# ioADuCM302x register map
Registers are 16-bit, access not given, no defined reset value unless marked. A register's access mark holds for its fields unless they carry their own. Addresses are absolute; registers are grouped by the start of their names; [hi:lo] are bit positions; {n}, {i} and the like mark numbered series.

## PMG0
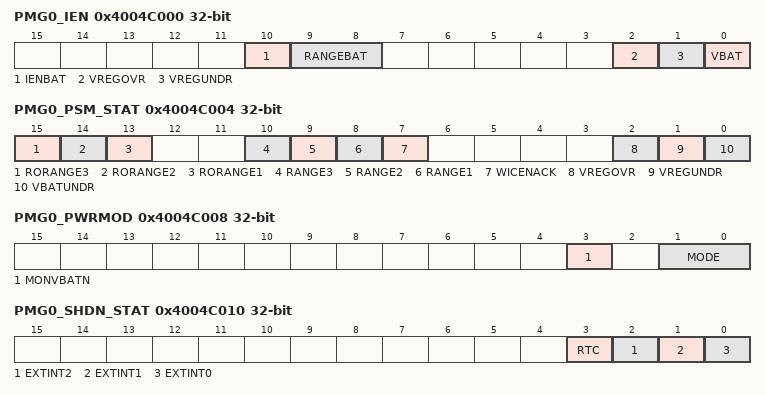
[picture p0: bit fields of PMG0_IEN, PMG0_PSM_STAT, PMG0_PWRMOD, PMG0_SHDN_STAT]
0x4004C000 PMG0_IEN 32-bit
  [10] IENBAT, [9:8] RANGEBAT, [2] VREGOVR, [1] VREGUNDR, [0] VBAT
0x4004C004 PMG0_PSM_STAT 32-bit
  [15] RORANGE3, [14] RORANGE2, [13] RORANGE1, [10] RANGE3, [9] RANGE2, [8] RANGE1, [7] WICENACK, [2] VREGOVR, [1] VREGUNDR, [0] VBATUNDR
0x4004C008 PMG0_PWRMOD 32-bit
  [3] MONVBATN, [1:0] MODE
0x4004C00C PMG0_PWRKEY 32-bit
  [15:0] VALUE
0x4004C010 PMG0_SHDN_STAT 32-bit
  [3] RTC, [2] EXTINT2, [1] EXTINT1, [0] EXTINT0
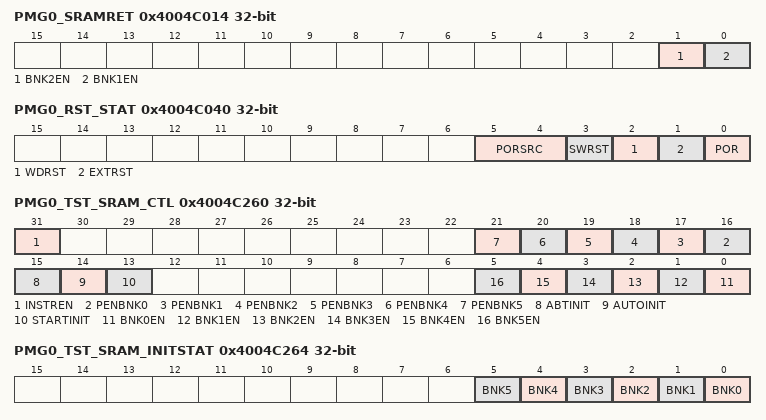
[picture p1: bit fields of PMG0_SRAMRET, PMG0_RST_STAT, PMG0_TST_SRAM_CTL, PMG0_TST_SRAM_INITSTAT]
0x4004C014 PMG0_SRAMRET 32-bit
  [1] BNK2EN, [0] BNK1EN
0x4004C040 PMG0_RST_STAT 32-bit
  [5:4] PORSRC, [3] SWRST, [2] WDRST, [1] EXTRST, [0] POR
0x4004C044 PMG0_CTL1 32-bit
  [0] HPBUCKEN
0x4004C260 PMG0_TST_SRAM_CTL 32-bit
  [31] INSTREN, [n+16] PENBNK{n} (n=0..5), [15] ABTINIT, [14] AUTOINIT, [13] STARTINIT, [n] BNK{n}EN (n=0..5)
0x4004C264 PMG0_TST_SRAM_INITSTAT 32-bit
  [n] BNK{n} (n=0..5)
0x4004C268 PMG0_TST_CLR_LATCH_GPIOS
0x4004C26C PMG0_TST_SCRPAD_IMG 32-bit
0x4004C270 PMG0_TST_SCRPAD_3V_RD 32-bit

## XINT0
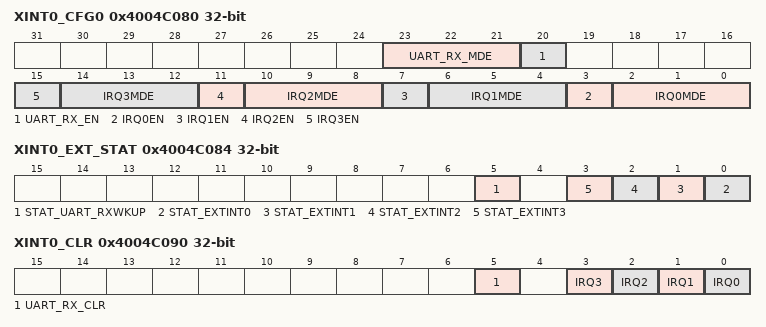
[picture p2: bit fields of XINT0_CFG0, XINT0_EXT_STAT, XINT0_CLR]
0x4004C080 XINT0_CFG0 32-bit
  [23:21] UART_RX_MDE, [20] UART_RX_EN, [4n+3] IRQ{n}EN (n=0..3), [4n+2:4n] IRQ{n}MDE (n=0..3)
0x4004C084 XINT0_EXT_STAT 32-bit
  [5] STAT_UART_RXWKUP, [n] STAT_EXTINT{n} (n=0..3)
0x4004C090 XINT0_CLR 32-bit
  [5] UART_RX_CLR, [n] IRQ{n} (n=0..3)
0x4004C094 XINT0_NMICLR 32-bit
  [0] CLR

## CLKG0
0x4004C10C CLKG0_OSC_KEY 32-bit
  [15:0] VALUE
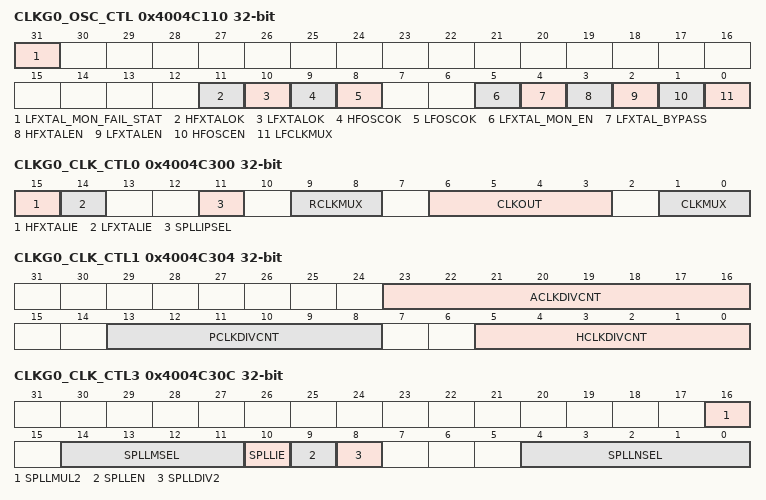
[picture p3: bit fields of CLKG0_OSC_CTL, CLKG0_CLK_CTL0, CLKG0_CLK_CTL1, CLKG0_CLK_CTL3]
0x4004C110 CLKG0_OSC_CTL 32-bit
  [31] LFXTAL_MON_FAIL_STAT, [11] HFXTALOK, [10] LFXTALOK, [9] HFOSCOK, [8] LFOSCOK, [5] LFXTAL_MON_EN, [4] LFXTAL_BYPASS, [3] HFXTALEN, [2] LFXTALEN, [1] HFOSCEN, [0] LFCLKMUX
0x4004C300 CLKG0_CLK_CTL0 32-bit
  [15] HFXTALIE, [14] LFXTALIE, [11] SPLLIPSEL, [9:8] RCLKMUX, [6:3] CLKOUT, [1:0] CLKMUX
0x4004C304 CLKG0_CLK_CTL1 32-bit
  [23:16] ACLKDIVCNT, [13:8] PCLKDIVCNT, [5:0] HCLKDIVCNT
0x4004C30C CLKG0_CLK_CTL3 32-bit
  [16] SPLLMUL2, [14:11] SPLLMSEL, [10] SPLLIE, [9] SPLLEN, [8] SPLLDIV2, [4:0] SPLLNSEL
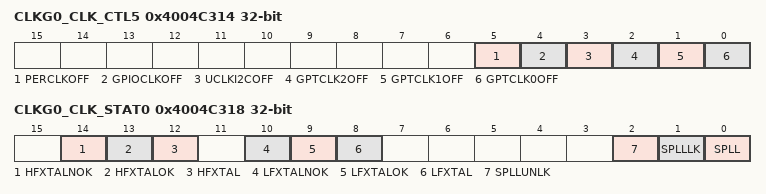
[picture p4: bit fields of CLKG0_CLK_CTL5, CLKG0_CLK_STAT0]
0x4004C314 CLKG0_CLK_CTL5 32-bit
  [5] PERCLKOFF, [4] GPIOCLKOFF, [3] UCLKI2COFF, [2] GPTCLK2OFF, [1] GPTCLK1OFF, [0] GPTCLK0OFF
0x4004C318 CLKG0_CLK_STAT0 32-bit
  [14] HFXTALNOK, [13] HFXTALOK, [12] HFXTAL, [10] LFXTALNOK, [9] LFXTALOK, [8] LFXTAL, [2] SPLLUNLK, [1] SPLLLK, [0] SPLL

## BUSM0
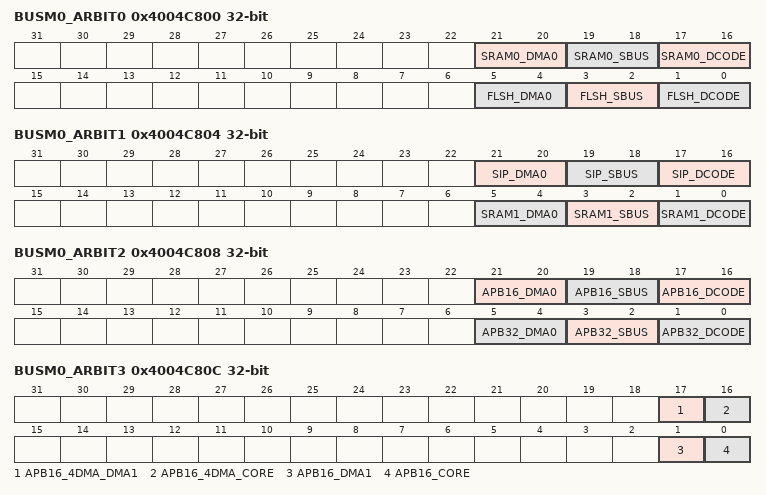
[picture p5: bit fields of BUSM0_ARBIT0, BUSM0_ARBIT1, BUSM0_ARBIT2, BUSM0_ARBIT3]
0x4004C800 BUSM0_ARBIT0 32-bit
  [21:20] SRAM0_DMA0, [19:18] SRAM0_SBUS, [17:16] SRAM0_DCODE, [5:4] FLSH_DMA0, [3:2] FLSH_SBUS, [1:0] FLSH_DCODE
0x4004C804 BUSM0_ARBIT1 32-bit
  [21:20] SIP_DMA0, [19:18] SIP_SBUS, [17:16] SIP_DCODE, [5:4] SRAM1_DMA0, [3:2] SRAM1_SBUS, [1:0] SRAM1_DCODE
0x4004C808 BUSM0_ARBIT2 32-bit
  [21:20] APB16_DMA0, [19:18] APB16_SBUS, [17:16] APB16_DCODE, [5:4] APB32_DMA0, [3:2] APB32_SBUS, [1:0] APB32_DCODE
0x4004C80C BUSM0_ARBIT3 32-bit
  [17] APB16_4DMA_DMA1, [16] APB16_4DMA_CORE, [1] APB16_DMA1, [0] APB16_CORE

## NVIC0
0xE000E004 NVIC0_INTNUM 32-bit
0xE000E010 NVIC0_STKSTA 32-bit
0xE000E014 NVIC0_STKLD 32-bit
0xE000E018 NVIC0_STKVAL 32-bit
0xE000E01C NVIC0_STKCAL 32-bit
0xE000E100 NVIC0_INTSETE0 32-bit
0xE000E104 NVIC0_INTSETE1 32-bit
0xE000E180 NVIC0_INTCLRE0 32-bit
0xE000E184 NVIC0_INTCLRE1 32-bit
0xE000E200 NVIC0_INTSETP0 32-bit
0xE000E204 NVIC0_INTSETP1 32-bit
0xE000E280 NVIC0_INTCLRP0 32-bit
0xE000E284 NVIC0_INTCLRP1 32-bit
0xE000E300 NVIC0_INTACT0 32-bit
0xE000E304 NVIC0_INTACT1 32-bit
{0xE000E400+4i} NVIC0_INTPRI{i} 32-bit (i=0..10)
0xE000ED00 NVIC0_INTCPID 32-bit
0xE000ED04 NVIC0_INTSTA 32-bit
0xE000ED08 NVIC0_INTVEC 32-bit
0xE000ED0C NVIC0_INTAIRC 32-bit
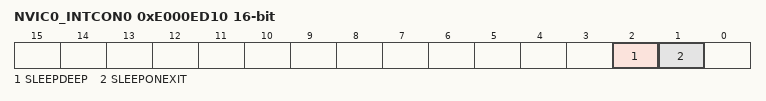
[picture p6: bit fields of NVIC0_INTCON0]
0xE000ED10 NVIC0_INTCON0
  [2] SLEEPDEEP, [1] SLEEPONEXIT
0xE000ED14 NVIC0_INTCON1 32-bit
0xE000ED18 NVIC0_INTSHPRIO0 32-bit
0xE000ED1C NVIC0_INTSHPRIO1 32-bit
0xE000ED20 NVIC0_INTSHPRIO3 32-bit
0xE000ED24 NVIC0_INTSHCSR 32-bit
0xE000ED28 NVIC0_INTCFSR 32-bit
0xE000ED2C NVIC0_INTHFSR 32-bit
0xE000ED30 NVIC0_INTDFSR 32-bit
0xE000ED34 NVIC0_INTMMAR 32-bit
0xE000ED38 NVIC0_INTBFAR 32-bit
0xE000ED3C NVIC0_INTAFSR 32-bit
0xE000ED40 NVIC0_INTPFR0 32-bit
0xE000ED44 NVIC0_INTPFR1 32-bit
0xE000ED48 NVIC0_INTDFR0 32-bit
0xE000ED4C NVIC0_INTAFR0 32-bit
{0xE000ED50+4i} NVIC0_INTMMFR{i} 32-bit (i=0..3)
{0xE000ED60+4i} NVIC0_INTISAR{i} 32-bit (i=0..4)
0xE000EF00 NVIC0_INTTRGI 32-bit
{0xE000EFC0+4i} NVIC0_INTPID{i} 32-bit (i=4..7)
{0xE000EFE0+4i} NVIC0_INTPID{i} 32-bit (i=0..3)
{0xE000EFF0+4i} NVIC0_INTCID{i} 32-bit (i=0..3)
